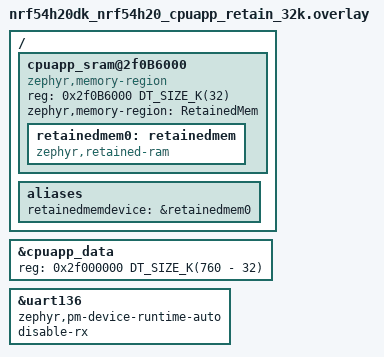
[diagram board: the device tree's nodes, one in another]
/ {
	cpuapp_sram@2f0B6000{
		compatible = "zephyr,memory-region", "mmio-sram";
		reg = <0x2f0B6000 DT_SIZE_K(32)>;
		zephyr,memory-region = "RetainedMem";
		status = "okay";

		retainedmem0: retainedmem {
			compatible = "zephyr,retained-ram";
			status = "okay";
		};
	};

	aliases {
		retainedmemdevice = &retainedmem0;
	};
};

&cpuapp_data {
	/* Shrink SRAM size to avoid overlap with retained memory region */
	reg = <0x2f000000 DT_SIZE_K(760 - 32)>;
};

&uart136 {
	zephyr,pm-device-runtime-auto;
	disable-rx;
};
